# STM32F042x6 register map
File version: 1.0
Registers are 32-bit, read-write, reset 0x0 unless marked. A register's access mark holds for its fields unless they carry their own. Offsets are from the block's base; [hi:lo] are bit positions; {n}, {i} and the like mark numbered series.

## IWDG — Independent WATCHDOG
Base 0x40003000
0x00 KR — IWDG Key register
  [15:0] KEY — Key value (write only, read 0000h)
0x04 PR — IWDG Prescaler register
  [2:0] PR — PR[2:0] (Prescaler divider)
0x08 RLR — IWDG Reload register
  [11:0] RL — Watchdog counter reload value
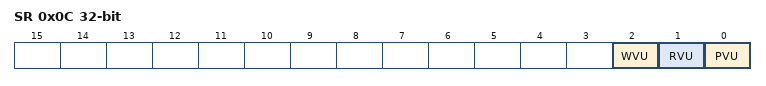
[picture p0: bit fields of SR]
0x0C SR — IWDG Status register
  [2] WVU — Watchdog counter window value update
  [1] RVU — Watchdog counter reload value update
  [0] PVU — Watchdog prescaler value update
0x10 WINR — IWDG Window register
  [11:0] WIN — Watchdog counter window value

## USB — Universal Serial Bus Full Speed Device
Base 0x40005C00
{0x0+4i} EP{i}R 16-bit (i=0..7) — USB Endpoint {i} register
0x40 CNTR 16-bit — Control register
0x44 ISTR 16-bit — Interrupt status register
0x48 FNR 16-bit — Frame number register
0x4C DADDR 16-bit — Device address register
0x50 BTABLE 16-bit — Buffer Table address register
0x54 LPMCSR 16-bit — LPM Control and Status register
0x58 BCDR 16-bit — Battery Charging detector register

## CRS — Clock Recovery System
Base 0x40006C00
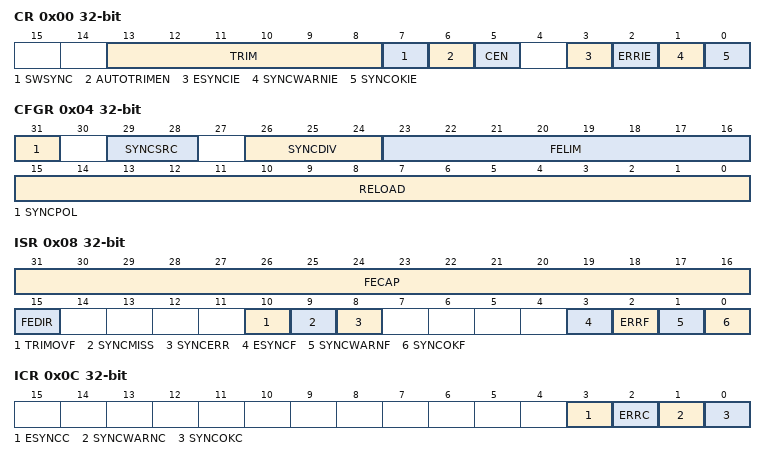
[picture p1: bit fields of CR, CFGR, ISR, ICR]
0x00 CR — CRS ccontrol register
  [13:8] TRIM, [7] SWSYNC, [6] AUTOTRIMEN, [5] CEN, [3] ESYNCIE, [2] ERRIE, [1] SYNCWARNIE, [0] SYNCOKIE
0x04 CFGR — CRS configuration register
  [31] SYNCPOL
    0=RISING (Synchro Active on rising edge (default)); 1=FALLING (Synchro Active on falling edge)
  [29:28] SYNCSRC
    0=GPIO (Synchro Signal source GPIO); 1=LSE (Synchro Signal source LSE); 2=USB (Synchro Signal source USB SOF (default))
  [26:24] SYNCDIV
    0=DIV_1 (Synchro Signal not divided (default)); 1=DIV_2 (Synchro Signal divided by 2); 2=DIV_4 (Synchro Signal divided by 4); 3=DIV_8 (Synchro Signal divided by 8); 4=DIV_16 (Synchro Signal divided by 16); 5=DIV_32 (Synchro Signal divided by 32); 6=DIV_64 (Synchro Signal divided by 64); 7=DIV_128 (Synchro Signal divided by 128)
  [23:16] FELIM
  [15:0] RELOAD
0x08 ISR — CRS interrupt and status register
  [31:16] FECAP
  [15] FEDIR
    0=UP (Upcounting direction, the actual frequency is above the target); 1=DOWN (Downcounting direction, the actual frequency is below the target)
  [10] TRIMOVF
  [9] SYNCMISS
  [8] SYNCERR
  [3] ESYNCF
  [2] ERRF
  [1] SYNCWARNF
  [0] SYNCOKF
0x0C ICR — CRS interrupt flag clear register
  [3] ESYNCC, [2] ERRC, [1] SYNCWARNC, [0] SYNCOKC

## PWR — Power Control
Base 0x40007000
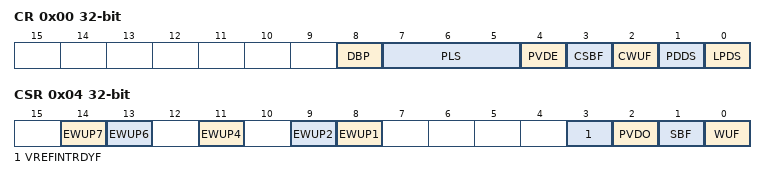
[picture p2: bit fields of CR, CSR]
0x00 CR — PWR power control register
  [8] DBP — Disable Backup Domain write protection
  [7:5] PLS — PLS[2:0] bits (PVD Level Selection)
    {v}=PVDLEVEL_{v} (Voltage threshold {v}) (v=0..7)
  [4] PVDE — Power Voltage Detector Enable
  [3] CSBF — Clear Standby Flag
  [2] CWUF — Clear Wakeup Flag
  [1] PDDS — Power Down Deepsleep
  [0] LPDS — Low-power Deepsleep
    0=MAIN (Voltage Regulator in main mode during deepsleep mode); 1=LOW_POWER (Voltage Regulator in low-power mode during deepsleep mode)
0x04 CSR — PWR power control/status register
  [14] EWUP7 — Enable WKUP pin 7
  [13] EWUP6 — Enable WKUP pin 6
  [11] EWUP4 — Enable WKUP pin 4
  [9] EWUP2 — Enable WKUP pin 2
  [8] EWUP1 — Enable WKUP pin 1
  [3] VREFINTRDYF — Internal voltage reference (VREFINT) ready flag
  [2] PVDO — PVD Output
  [1] SBF — Standby Flag
  [0] WUF — Wakeup Flag

## CEC — HDMI-CEC
Base 0x40007800
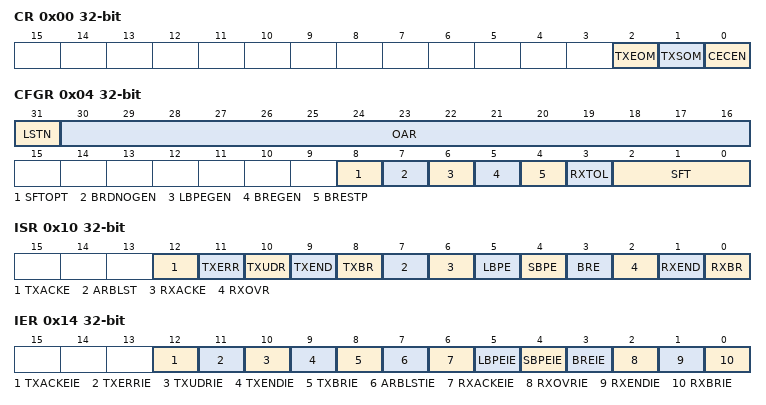
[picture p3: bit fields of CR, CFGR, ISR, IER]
0x00 CR — CEC control register
  [2] TXEOM — CEC Tx End Of Message
  [1] TXSOM — CEC Tx Start Of Message
  [0] CECEN — CEC Enable
0x04 CFGR — CEC configuration register
  [31] LSTN — CEC Listen mode
  [30:16] OAR — CEC Own Address
  [8] SFTOPT — CEC Signal Free Time optional
  [7] BRDNOGEN — CEC Broadcast No Error generation
  [6] LBPEGEN — CEC Long Bit Period Error gener
  [5] BREGEN — CEC Bit Rising Error generation
  [4] BRESTP — CEC Rx Stop
  [3] RXTOL — CEC Tolerance
  [2:0] SFT — CEC Signal Free Time
0x08 TXDR — CEC Tx data register
  [7:0] TXD — CEC Tx Data
0x0C RXDR — CEC Rx Data Register
  [7:0] RXD — CEC Rx Data
0x10 ISR — CEC Interrupt and Status Register
  [12] TXACKE — CEC Tx Missing Acknowledge
  [11] TXERR — CEC Tx-Error
  [10] TXUDR — CEC Tx-Buffer Underrun
  [9] TXEND — CEC End of Transmission
  [8] TXBR — CEC Tx Byte Request
  [7] ARBLST — CEC Arbitration Lost
  [6] RXACKE — CEC Rx Missing Acknowledge
  [5] LBPE — CEC Rx Long Bit period Error
  [4] SBPE — CEC Rx Short Bit period Error
  [3] BRE — CEC Rx Bit Rising Error
  [2] RXOVR — CEC Rx-Overrun
  [1] RXEND — CEC End Of Reception
  [0] RXBR — CEC Rx-Byte Received
0x14 IER — CEC interrupt enable register
  [12] TXACKEIE — CEC Tx Missing Acknowledge IT Enable
  [11] TXERRIE — CEC Tx-Error IT Enable
  [10] TXUDRIE — CEC Tx-Buffer Underrun IT Enable
  [9] TXENDIE — CEC End of Transmission IT Enable
  [8] TXBRIE — CEC Tx Byte Request IT Enable
  [7] ARBLSTIE — CEC Arbitration Lost IT Enable
  [6] RXACKEIE — CEC Rx Missing Acknowledge IT Enable
  [5] LBPEIE — CEC Rx Long Bit period Error IT Enable
  [4] SBPEIE — CEC Rx Short Bit period Error IT Enable
  [3] BREIE — CEC Rx Bit Rising Error IT Enable
  [2] RXOVRIE — CEC Rx-Overrun IT Enable
  [1] RXENDIE — CEC End Of Reception IT Enable
  [0] RXBRIE — CEC Rx-Byte Received IT Enable
